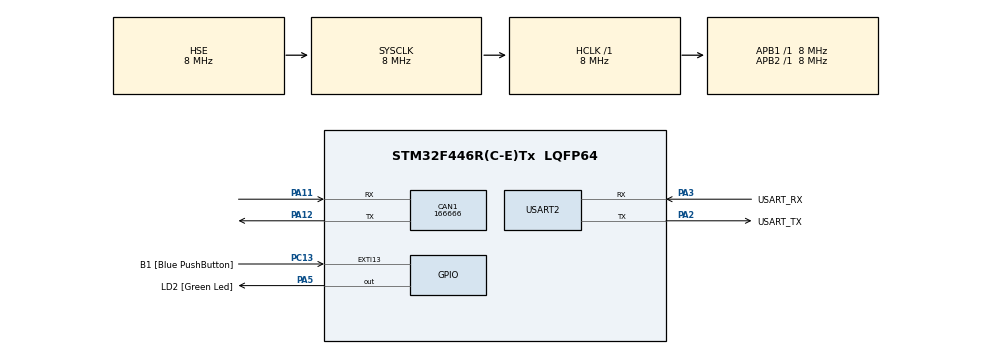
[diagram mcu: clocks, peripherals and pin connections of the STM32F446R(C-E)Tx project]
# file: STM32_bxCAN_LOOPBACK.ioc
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CAN1.CalculateBaudRate=166666
CAN1.CalculateTimeBit=6000
CAN1.CalculateTimeQuantum=2000.0
Mcu.Family=STM32F4
Mcu.Name=STM32F446R(C-E)Tx
Mcu.Package=LQFP64
NVIC.PriorityGroup=NVIC_PRIORITYGROUP_0
NVIC.USART2_IRQn=true\:0\:0\:false\:false\:true\:true\:true\:true
PA11.Mode=CAN_Activate
PA11.Signal=CAN1_RX
PA12.Mode=CAN_Activate
PA12.Signal=CAN1_TX
PA13.GPIO_Label=TMS
PA13.Mode=Serial_Wire
PA13.Signal=SYS_JTMS-SWDIO
PA14.GPIO_Label=TCK
PA14.Mode=Serial_Wire
PA14.Signal=SYS_JTCK-SWCLK
PA2.GPIO_Label=USART_TX
PA2.Mode=Asynchronous
PA2.Signal=USART2_TX
PA3.GPIO_Label=USART_RX
PA3.Mode=Asynchronous
PA3.Signal=USART2_RX
PA5.GPIO_Label=LD2 [Green Led]
PA5.Signal=GPIO_Output
PB3.GPIO_Label=SWO
PB3.Signal=SYS_JTDO-SWO
PC13.GPIO_Label=B1 [Blue PushButton]
PC13.GPIO_ModeDefaultEXTI=GPIO_MODE_IT_FALLING
PC13.Signal=GPXTI13
PC14-OSC32_IN.Mode=LSE-External-Oscillator
PC14-OSC32_IN.Signal=RCC_OSC32_IN
PC15-OSC32_OUT.Mode=LSE-External-Oscillator
PC15-OSC32_OUT.Signal=RCC_OSC32_OUT
PH0-OSC_IN.Mode=HSE-External-Oscillator
PH0-OSC_IN.Signal=RCC_OSC_IN
PH1-OSC_OUT.Mode=HSE-External-Oscillator
PH1-OSC_OUT.Signal=RCC_OSC_OUT
ProjectManager.HeapSize=0x200
ProjectManager.StackSize=0x400
ProjectManager.TargetToolchain=STM32CubeIDE
RCC.48MHZClocksFreq_Value=84000000
RCC.AHBFreq_Value=8000000
RCC.APB1Freq_Value=8000000
RCC.APB1TimFreq_Value=8000000
RCC.APB2Freq_Value=8000000
RCC.APB2TimFreq_Value=8000000
RCC.CortexFreq_Value=8000000
RCC.FLatency-AdvancedSettings=FLASH_LATENCY_0
RCC.HCLKFreq_Value=8000000
RCC.HSE_VALUE=8000000
RCC.HSI_VALUE=16000000
RCC.PLLM=4
RCC.PLLN=64
RCC.PLLSourceVirtual=RCC_PLLSOURCE_HSE
RCC.SYSCLKFreq_VALUE=8000000
RCC.SYSCLKSource=RCC_SYSCLKSOURCE_HSE
RCC.USBFreq_Value=64000000
RCC.VCOOutputFreq_Value=128000000
USART2.VirtualMode=VM_ASYNC
board=NUCLEO-F446RE

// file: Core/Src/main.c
/* USER CODE BEGIN Header */
/**
  ******************************************************************************
  * @file           : main.c
  * @brief          : Main program body
  ******************************************************************************
  * @attention
  *
  * Copyright (c) 2024 STMicroelectronics.
  * All rights reserved.
  *
  * This software is licensed under terms that can be found in the LICENSE file
  * in the root directory of this software component.
  * If no LICENSE file comes with this software, it is provided AS-IS.
  *
  ******************************************************************************
  */
/* USER CODE END Header */
#include "main.h"
#include <stdio.h>
#include <string.h>

CAN_HandleTypeDef hcan1;

UART_HandleTypeDef huart2;

void SystemClock_Config(void);
static void MX_GPIO_Init(void);
static void MX_USART2_UART_Init(void);
static void MX_CAN1_Init(void);
void CAN1_TX(void);

int main(void)
{

  /* MCU Configuration--------------------------------------------------------*/

  /* Reset of all peripherals, Initializes the Flash interface and the Systick. */
  HAL_Init();

  /* Configure the system clock */
  SystemClock_Config();

  /* Initialize all configured peripherals */
  MX_GPIO_Init();
  MX_USART2_UART_Init();
  MX_CAN1_Init();
  if(HAL_CAN_Init(&hcan1) != HAL_OK)
  {
	  Error_Handler();
  }
  /* USER CODE BEGIN 2 */

  if(HAL_CAN_Start(&hcan1) != HAL_OK)
  {
	  Error_Handler();
  }

  char buffer[50];
  sprintf(buffer, "Message Transmitted via CAN\r\n");
  	HAL_UART_Transmit(&huart2, (uint8_t*)buffer,(strlen(buffer)), HAL_MAX_DELAY);

  /* USER CODE END 2 */

  /* Infinite loop */
  while (1)
  {

  }
}

void CAN1_TX(void)
{
	CAN_TxHeaderTypeDef TxHeader;
	uint8_t hello[8] = "Hello\r\n";
	char buffer[50];

	TxHeader.DLC = 5;
	TxHeader.StdId = 1;
	TxHeader.IDE = CAN_ID_STD;
	TxHeader.RTR = CAN_RTR_DATA; //Remote frame is also a request frame
	if(HAL_CAN_AddTxMessage(&hcan1, &TxHeader,(uint8_t* )hello, CAN_TX_MAILBOX0) != HAL_OK)
	{
		Error_Handler();
	}

	while(HAL_CAN_IsTxMessagePending(&hcan1, CAN_TX_MAILBOX0));

	sprintf(buffer, "Message Transmitted via CAN\r\n");
	HAL_UART_Transmit(&huart2, (uint8_t*)buffer,(strlen(buffer)), HAL_MAX_DELAY);

}
void SystemClock_Config(void)
{
  RCC_OscInitTypeDef RCC_OscInitStruct = {0};
  RCC_ClkInitTypeDef RCC_ClkInitStruct = {0};

  /** Configure the main internal regulator output voltage
  */
  __HAL_RCC_PWR_CLK_ENABLE();
  __HAL_PWR_VOLTAGESCALING_CONFIG(PWR_REGULATOR_VOLTAGE_SCALE3);

  /** Initializes the RCC Oscillators according to the specified parameters
  * in the RCC_OscInitTypeDef structure.
  */
  RCC_OscInitStruct.OscillatorType = RCC_OSCILLATORTYPE_HSE;
  RCC_OscInitStruct.HSEState = RCC_HSE_ON;
  RCC_OscInitStruct.PLL.PLLState = RCC_PLL_NONE;
  if (HAL_RCC_OscConfig(&RCC_OscInitStruct) != HAL_OK)
  {
    Error_Handler();
  }

  /** Initializes the CPU, AHB and APB buses clocks
  */
  RCC_ClkInitStruct.ClockType = RCC_CLOCKTYPE_HCLK|RCC_CLOCKTYPE_SYSCLK
                              |RCC_CLOCKTYPE_PCLK1|RCC_CLOCKTYPE_PCLK2;
  RCC_ClkInitStruct.SYSCLKSource = RCC_SYSCLKSOURCE_HSE;
  RCC_ClkInitStruct.AHBCLKDivider = RCC_SYSCLK_DIV1;
  RCC_ClkInitStruct.APB1CLKDivider = RCC_HCLK_DIV1;
  RCC_ClkInitStruct.APB2CLKDivider = RCC_HCLK_DIV1;

  if (HAL_RCC_ClockConfig(&RCC_ClkInitStruct, FLASH_LATENCY_0) != HAL_OK)
  {
    Error_Handler();
  }
}

static void MX_CAN1_Init(void)
{

//  hcan1.Instance = CAN1;
//  hcan1.Init.Mode = CAN_MODE_NORMAL;
//  hcan1.Init.SyncJumpWidth = CAN_SJW_1TQ;
//  hcan1.Init.TimeSeg1 = CAN_BS1_1TQ;
//  hcan1.Init.TimeSeg2 = CAN_BS2_1TQ;
//  hcan1.Init.TimeTriggeredMode = DISABLE;
//  hcan1.Init.AutoBusOff = DISABLE;
//  hcan1.Init.AutoWakeUp = DISABLE;
//  hcan1.Init.AutoRetransmission = DISABLE;
//  hcan1.Init.ReceiveFifoLocked = DISABLE;
//  hcan1.Init.TransmitFifoPriority = DISABLE;

  hcan1.Instance = CAN1;
  hcan1.Init.Prescaler = 1;
  hcan1.Init.Mode = CAN_MODE_LOOPBACK;
  hcan1.Init.AutoBusOff = DISABLE;
  hcan1.Init.AutoRetransmission = DISABLE;
  hcan1.Init.AutoWakeUp = DISABLE;
  hcan1.Init.ReceiveFifoLocked = DISABLE;
  hcan1.Init.TimeTriggeredMode = DISABLE;
  hcan1.Init.TransmitFifoPriority = DISABLE;

  //CAN COMMUNICATION SETTINGS - BIT TIMINGS
  hcan1.Init.SyncJumpWidth = CAN_SJW_1TQ;
  hcan1.Init.TimeSeg1 = CAN_BS1_5TQ;
  hcan1.Init.TimeSeg2 = CAN_BS2_2TQ;
  if (HAL_CAN_Init(&hcan1) != HAL_OK)
  {
    Error_Handler();
  }

}

static void MX_USART2_UART_Init(void)
{

  huart2.Instance = USART2;
  huart2.Init.BaudRate = 115200;
  huart2.Init.WordLength = UART_WORDLENGTH_8B;
  huart2.Init.StopBits = UART_STOPBITS_1;
  huart2.Init.Parity = UART_PARITY_NONE;
  huart2.Init.Mode = UART_MODE_TX_RX;
  huart2.Init.HwFlowCtl = UART_HWCONTROL_NONE;
  huart2.Init.OverSampling = UART_OVERSAMPLING_16;
  if (HAL_UART_Init(&huart2) != HAL_OK)
  {
    Error_Handler();
  }

}

static void MX_GPIO_Init(void)
{
  GPIO_InitTypeDef GPIO_InitStruct = {0};

  /* GPIO Ports Clock Enable */
  __HAL_RCC_GPIOC_CLK_ENABLE();
  __HAL_RCC_GPIOH_CLK_ENABLE();
  __HAL_RCC_GPIOA_CLK_ENABLE();
  __HAL_RCC_GPIOB_CLK_ENABLE();

  /*Configure GPIO pin Output Level */
  HAL_GPIO_WritePin(LD2_GPIO_Port, LD2_Pin, GPIO_PIN_RESET);

  /*Configure GPIO pin : B1_Pin */
  GPIO_InitStruct.Pin = B1_Pin;
  GPIO_InitStruct.Mode = GPIO_MODE_IT_FALLING;
  GPIO_InitStruct.Pull = GPIO_NOPULL;
  HAL_GPIO_Init(B1_GPIO_Port, &GPIO_InitStruct);

  /*Configure GPIO pin : LD2_Pin */
  GPIO_InitStruct.Pin = LD2_Pin;
  GPIO_InitStruct.Mode = GPIO_MODE_OUTPUT_PP;
  GPIO_InitStruct.Pull = GPIO_NOPULL;
  GPIO_InitStruct.Speed = GPIO_SPEED_FREQ_LOW;
  HAL_GPIO_Init(LD2_GPIO_Port, &GPIO_InitStruct);

}

void Error_Handler(void)
{
  __disable_irq();
  while (1)
  {
  }
}
